# MM32F031xxn register map
File version: 1.92
CPU: CM0 r0p0, little endian, no MPU, no FPU, 2 interrupt priority bits
Registers are 32-bit, read-write, reset 0x0 unless marked. A register's access mark holds for its fields unless they carry their own. Offsets are from the block's base; [hi:lo] are bit positions.

## TIM14 — Basic purpose timer
Base 0x40014000
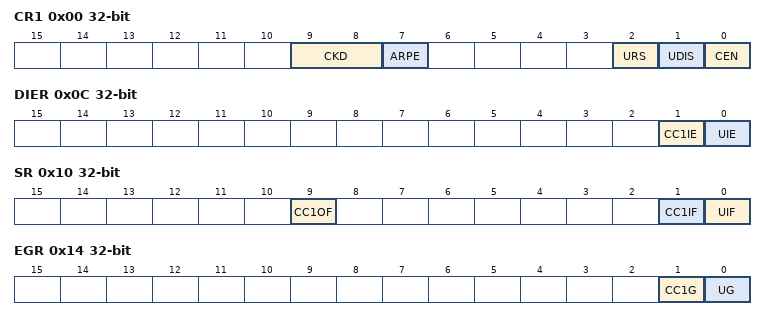
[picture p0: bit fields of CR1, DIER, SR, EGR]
0x00 CR1 — control register 1
  [9:8] CKD — Clock division
  [7] ARPE — Auto-reload preload enable
  [2] URS — Update request source
  [1] UDIS — Update disable
  [0] CEN — Counter enable
0x0C DIER — DMA/Interrupt enable register
  [1] CC1IE — Capture/Compare 1 interrupt enable
  [0] UIE — Update interrupt enable
0x10 SR — status register
  [9] CC1OF — Capture/Compare 1 overcapture flag
  [1] CC1IF — Capture/Compare 1 interrupt flag
  [0] UIF — Update interrupt flag
0x14 EGR wo — event generation register
  [1] CC1G — Capture/Compare 1 generation
  [0] UG — Update generation
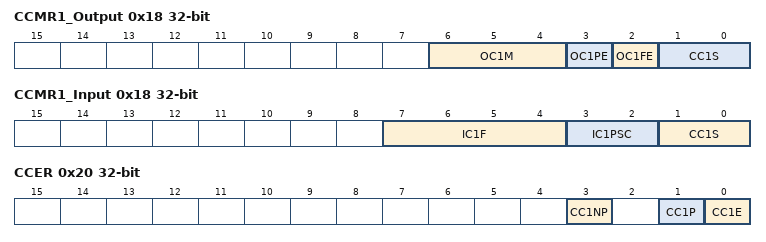
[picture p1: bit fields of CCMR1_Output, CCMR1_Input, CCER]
0x18 CCMR1_Output — capture/compare mode register 1 (output mode)
  [6:4] OC1M — Output compare 1 mode
  [3] OC1PE — Output compare 1 preload enable
  [2] OC1FE — Output compare 1 fast enable
  [1:0] CC1S — Capture/Compare 2 output enable
0x18 CCMR1_Input (alternate view of CCMR1_Output) — capture/compare mode register 1 (input mode)
  [7:4] IC1F — Input capture 1 filter
  [3:2] IC1PSC — Input capture 1 prescaler
  [1:0] CC1S — Capture/compare 1 selection
0x20 CCER — capture/compare enable register
  [3] CC1NP — Capture/Compare 1 complementary output polarity
  [1] CC1P — Capture/Compare 1 output polarity
  [0] CC1E — Capture/Compare 1 output enable
0x24 CNT — counter
  [15:0] CNT — Counter value
0x28 PSC — prescaler
  [15:0] PSC — Prescaler value
0x2C ARR — auto-reload register
  [15:0] ARR — auto-reload value
0x34 CCR1 — capture/compare register 1
  [15:0] CCR1 — Capture/Compare 1 value

## TIM16 — Basic purpose timer
Base 0x40014400
Same registers: TIM17 0x40014800
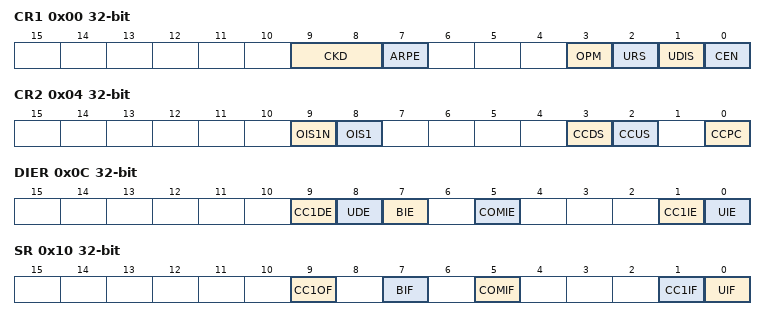
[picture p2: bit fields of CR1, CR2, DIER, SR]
0x00 CR1 — control register 1
  [9:8] CKD — Clock division
  [7] ARPE — Auto-reload preload enable
  [3] OPM — One pulse mode
  [2] URS — Update request source
  [1] UDIS — Update disable
  [0] CEN — Counter enable
0x04 CR2 — control register 2
  [9] OIS1N — Output idle state 1
  [8] OIS1 — Output idle state 1
  [3] CCDS — Capture/Compare DMA selection
  [2] CCUS — Capture/compare control update selection
  [0] CCPC — Capture/compare preloaded control
0x0C DIER — DMA/Interrupt enable register
  [9] CC1DE — Capture/Compare 1 DMA request enable
  [8] UDE — Update DMA request enable
  [7] BIE — break interrupt enable
  [5] COMIE — Compare interrupt enable
  [1] CC1IE — Capture/Compare 1 interrupt enable
  [0] UIE — Update interrupt enable
0x10 SR — status register
  [9] CC1OF — Capture/Compare 1 overcapture flag
  [7] BIF — Break interrupt flag
  [5] COMIF — COM interrupt flag
  [1] CC1IF — Capture/Compare 1 interrupt flag
  [0] UIF — Update interrupt flag
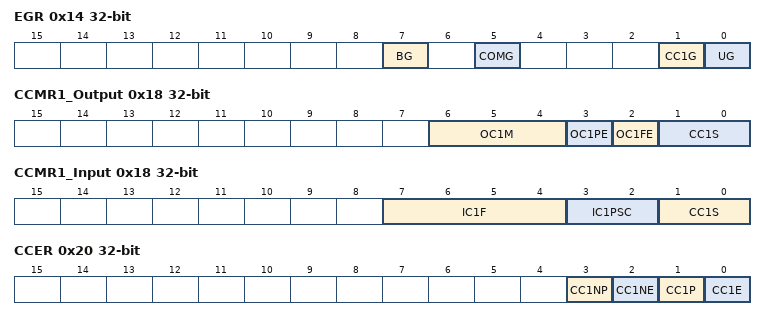
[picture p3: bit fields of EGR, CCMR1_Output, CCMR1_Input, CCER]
0x14 EGR — event generation register
  [7] BG — Break generation
  [5] COMG — Capture/Compare control update generation
  [1] CC1G — Capture/compare 1 generation
  [0] UG — Update generation
0x18 CCMR1_Output — capture/compare mode register 1 (output mode)
  [6:4] OC1M — Output compare 1 mode
  [3] OC1PE — Output compare 1 preload enable
  [2] OC1FE — Output compare 1 fast enable
  [1:0] CC1S — Capture/Compare 2 output enable
0x18 CCMR1_Input (alternate view of CCMR1_Output) — capture/compare mode register 1 (input mode)
  [7:4] IC1F — Input capture 1 filter
  [3:2] IC1PSC — Input capture 1 prescaler
  [1:0] CC1S — Capture/compare 1 selection
0x20 CCER — capture/compare enable register
  [3] CC1NP — Capture/Compare 1 complementary output Polarity
  [2] CC1NE — Capture/Compare 1 complementary output enable
  [1] CC1P — Capture/Compare 1 output polarity
  [0] CC1E — Capture/Compare 1 output enable
0x24 CNT — counter
  [15:0] CNT — Counter value
0x28 PSC — prescaler
  [15:0] PSC — Prescaler value
0x2C ARR — auto-reload register
  [15:0] ARR — Auto reload value
0x30 RCR — repetition counter register
  [7:0] REP — Repetition counter value
0x34 CCR1 — capture/compare register 1
  [15:0] CCR1 — Capture/Compare 1 value
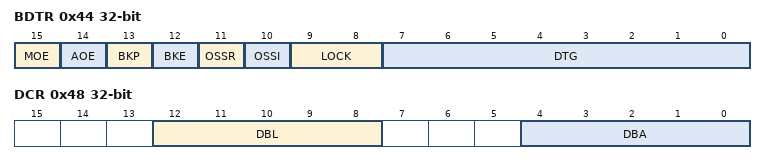
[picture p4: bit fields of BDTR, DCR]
0x44 BDTR — break and dead-time register
  [15] MOE — Main output enable
  [14] AOE — Automatic output enable
  [13] BKP — Break polarity
  [12] BKE — Break enable
  [11] OSSR — Off-state selection for run mode
  [10] OSSI — Off-state selection for idle mode
  [9:8] LOCK — Lock configuration
  [7:0] DTG — Dead-time generation setup
0x48 DCR wo — DMA control register
  [12:8] DBL — DMA burst length
  [4:0] DBA — DMA base address
0x4C DMAR wo — DMA address for full transfer
  [15:0] DMAB — DMA register for burst accesses

## UART1 — Universal asynchronous receiver transmitter
Base 0x40013800
Same registers: UART2 0x40004400
0x00 TDR — Transmit data register
  [7:0] TXREG
0x04 RDR ro — Receive data register
  [7:0] RXREG
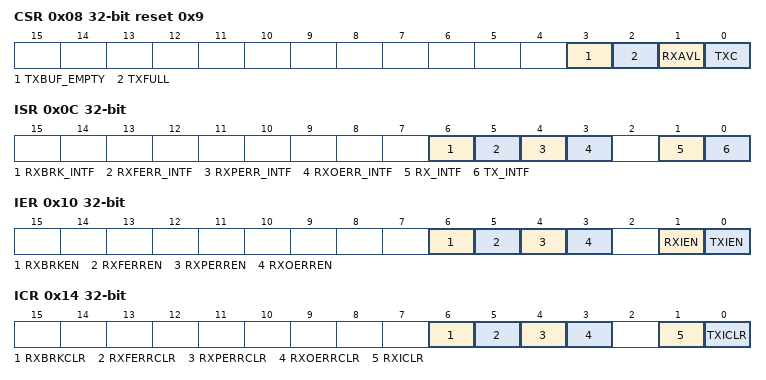
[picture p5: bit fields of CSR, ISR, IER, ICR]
0x08 CSR ro reset 0x9 — Current status register
  [3] TXBUF_EMPTY — Transmit buffer empty flag bit
  [2] TXFULL — Transmit buffer full flag bit
  [1] RXAVL — Receive valid data flag bit
  [0] TXC — Transmit complete flag bit
0x0C ISR ro — Interrupt status register
  [6] RXBRK_INTF — Receive frame break interrupt flag bit
  [5] RXFERR_INTF — Frame error interrupt flag bit
  [4] RXPERR_INTF — Parity error interrupt flag bit
  [3] RXOERR_INTF — Receive overflow error interrupt flag bit
  [1] RX_INTF — Receive valid data interrupt flag bit
  [0] TX_INTF — Transmit buffer empty interrupt flag bit
0x10 IER — Interrupt enable register
  [6] RXBRKEN — Receive frame break interrupt enable bit
  [5] RXFERREN — Frame error interrupt enable bit
  [4] RXPERREN — Parity error interrupt enable bit
  [3] RXOERREN — Receive overflow error interrupt enable bit
  [1] RXIEN — Receive buffer interrupt enable bit
  [0] TXIEN — Transmit buffer empty interrupt enable bit
0x14 ICR wo
  [6] RXBRKCLR — Receive frame break interrupt clear bit
  [5] RXFERRCLR — Frame error interrupt clear bit
  [4] RXPERRCLR — Parity error interrupt clear bit
  [3] RXOERRCLR — Receive overflow error interrupt clear bit
  [1] RXICLR — Receive interrupt clear bit
  [0] TXICLR — Transmit buffer empty interrupt clear bit
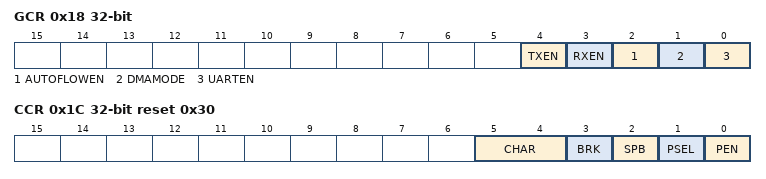
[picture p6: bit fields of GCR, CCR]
0x18 GCR — Global control register
  [4] TXEN — Enable transmit
  [3] RXEN — Enable receive
  [2] AUTOFLOWEN — Automatic flow control enable bit
  [1] DMAMODE — DMA mode selection bit
  [0] UARTEN — UART mode selection bit
0x1C CCR reset 0x30 — common control register
  [5:4] CHAR — UART width bit
  [3] BRK — UART transmit frame break
  [2] SPB — Stop bit selection
  [1] PSEL — Parity selection bit
  [0] PEN — Parity enable bit
0x20 BRR reset 0x1 — Baud rate register
  [15:0] DIV_MANTISSA — Mantissa part of UARTDIV
0x24 FRA — Fractional baud rate register
  [3:0] DIV_Fraction — Fractional part of UARTDIV

## WWDG — Window watchdog
Base 0x40002C00
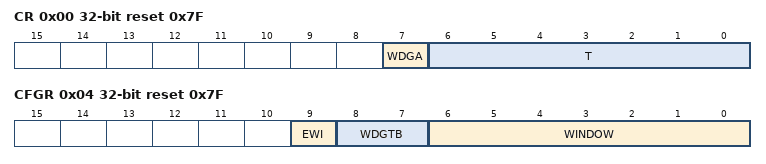
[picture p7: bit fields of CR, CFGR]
0x00 CR reset 0x7F — Control register
  [7] WDGA — Activation bit
  [6:0] T — 7-bit counter
0x04 CFGR reset 0x7F — Configuration register
  [9] EWI — Early wakeup interrupt
  [8:7] WDGTB — Timer base
  [6:0] WINDOW — 7-bit window value
0x08 SR ro — Status register
  [0] EWIF — Early wakeup interrupt flag
